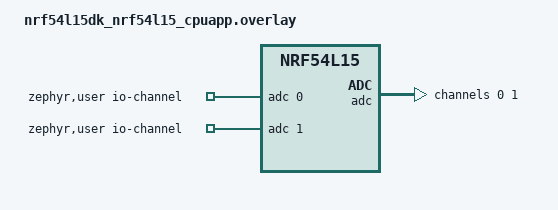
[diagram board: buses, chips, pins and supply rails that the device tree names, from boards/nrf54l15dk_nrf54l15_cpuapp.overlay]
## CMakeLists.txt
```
cmake_minimum_required(VERSION 3.20.0)
find_package(Zephyr REQUIRED HINTS $ENV{ZEPHYR_BASE})

project(nrf_peripheral_dmm)

target_sources(app PRIVATE src/main.c)
```

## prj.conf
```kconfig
# Button and LED library
CONFIG_DK_LIBRARY=y

# Add logging
CONFIG_LOG=y

# Add ADC support
CONFIG_ADC=y

# Increase stack size for the main thread and System Workqueue
CONFIG_SYSTEM_WORKQUEUE_STACK_SIZE=2048
CONFIG_MAIN_STACK_SIZE=2048

# Bluetooth LE
CONFIG_BT=y
CONFIG_BT_PERIPHERAL=y
# Replace ZZZZZ with a unique identifier to make scanning for advertisers easier
CONFIG_BT_DEVICE_NAME="ZZZZZ_PMIC"
CONFIG_BT_MAX_CONN=1
```

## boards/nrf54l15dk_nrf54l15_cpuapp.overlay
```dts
/*
 * SPDX-License-Identifier: Apache-2.0
 *
 * Copyright (c) 2025 Nordic Semiconductor ASA
 */
/ {
	zephyr,user {
		io-channels = <&adc 0>, <&adc 1>;
	};
};

&adc {
	#address-cells = <1>;
	#size-cells = <0>;
	status = "okay";
	channel@0 {
		reg = <0>;
		zephyr,gain = "ADC_GAIN_1_4";
		zephyr,reference = "ADC_REF_INTERNAL";
		zephyr,acquisition-time = <ADC_ACQ_TIME_DEFAULT>;
		zephyr,input-positive = <NRF_SAADC_AIN4>; /* P1.11 for the nRF54L15 DK, BOOST/VOUT on pmic */
		zephyr,resolution = <14>;
	};
	channel@1 {
		reg = <1>;
		zephyr,gain = "ADC_GAIN_1_4";
		zephyr,reference = "ADC_REF_INTERNAL";
		zephyr,acquisition-time = <ADC_ACQ_TIME_DEFAULT>;
		zephyr,input-positive = <NRF_SAADC_AIN5>; /* Example: P1.12 for the nRF54L15 DK, LSLDO OUT on pmic */
		zephyr,resolution = <14>;
	};
};
```

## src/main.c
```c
#include <zephyr/kernel.h>


int main(void)
{
        return 0;
}
```
